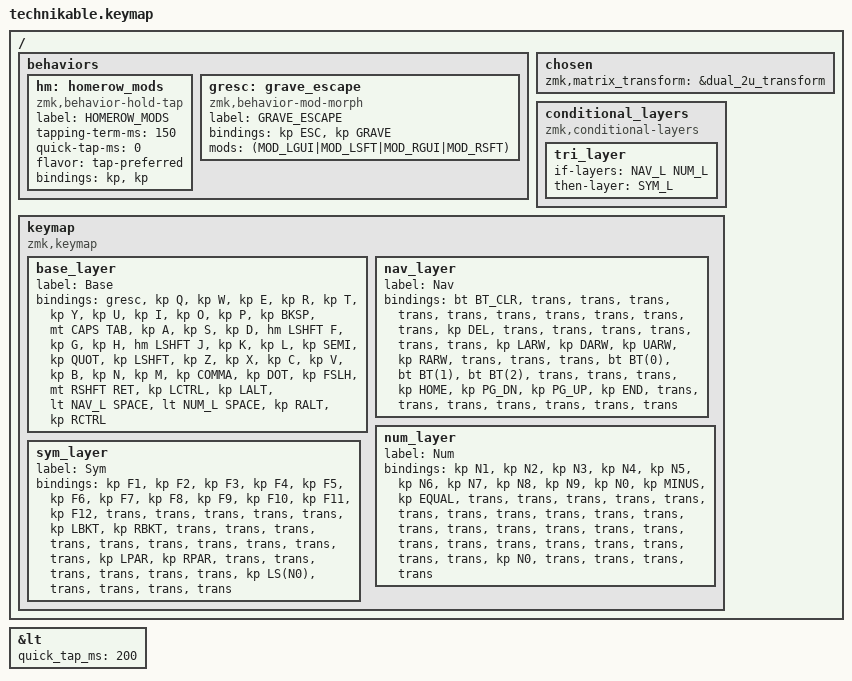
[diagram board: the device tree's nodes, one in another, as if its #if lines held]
/*
 * Copyright (c) 2022 Pete Johanson
 *
 * SPDX-License-Identifier: MIT
 */

#include <behaviors.dtsi>
#include <dt-bindings/zmk/keys.h>
#include <dt-bindings/zmk/bt.h>
#include <dt-bindings/zmk/outputs.h>

#define QWERTY_BASE 1

// #define TBLE_ORTHO   true
#define TBLE_MIT     true
// #define TBLE_DUAL_2U true

#define BAS_L 0
#define NAV_L 1
#define NUM_L 2
#define SYM_L 3

// Using layer taps on thumbs, having quick tap as well helps w/ repeating space/backspace
&lt { quick_tap_ms = <200>; };

#define BT(n) BT_SEL n

/ {
    behaviors {
        hm: homerow_mods {
	    compatible = "zmk,behavior-hold-tap";
	    label = "HOMEROW_MODS";
	    #binding-cells = <2>;
	    tapping-term-ms = <150>;
	    quick-tap-ms = <0>;
	    flavor = "tap-preferred";
	    bindings = <&kp>, <&kp>;
        };
        gresc: grave_escape {
            compatible = "zmk,behavior-mod-morph";
            label = "GRAVE_ESCAPE";
            #binding-cells = <0>;
            bindings = <&kp ESC>, <&kp GRAVE>;
            mods = <(MOD_LGUI|MOD_LSFT|MOD_RGUI|MOD_RSFT)>;
        };
    };
    chosen {
       zmk,matrix_transform =
#ifdef TBLE_DUAL_2U
                       &dual_2u_transform;
#elif defined(TBLE_MIT)
                       &mit_transform;
#else
                       &ortho_transform;
#endif
    };

    conditional_layers {
        compatible = "zmk,conditional-layers";
	tri_layer {
	    if-layers = <NAV_L NUM_L>;
	    then-layer = <SYM_L>;
	};
    };

    keymap {
        compatible = "zmk,keymap";

        base_layer {
            label = "Base";
            bindings = <
#ifdef QWERTY_BASE
 &gresc    &kp Q      &kp W      &kp E     &kp R           &kp T          &kp Y         &kp U            &kp I       &kp O      &kp P         &kp BKSP
 &mt CAPS TAB    &kp A      &kp S      &kp D     &hm LSHFT F     &kp G          &kp H         &hm LSHFT J      &kp K       &kp L      &kp SEMI      &kp QUOT
 &kp LSHFT       &kp Z      &kp X      &kp C     &kp V           &kp B          &kp N         &kp M            &kp COMMA   &kp DOT    &kp FSLH      &mt RSHFT RET
#else
 &kp ESC    &kp Q      &kp W      &kp F       &kp P          &kp B          &kp J            &kp L          &kp U       &kp Y      &kp QUOT     &kp BKSP
 &kp TAB    &kp A      &kp R      &kp S       &kp T          &kp G          &kp M            &kp N          &kp E       &kp I      &kp O        &kp QUOT
 &kp LSHFT  &kp Z      &kp X      &kp C       &kp D          &kp V          &kp K            &kp H          &kp COMMA   &kp DOT    &kp FSLH     &kp RET
#endif
#ifdef TBLE_DUAL_2U
                       &kp LCTRL  &kp LALT      &lt NAV_L SPACE                &lt NUM_L SPACE              &kp RALT    &kp RCTRL
#elif defined(TBLE_MIT)
                       &kp LCTRL  &kp LGUI    &lt NAV_L LBKT     &kp SPACE       &lt NUM_L RBKT      &kp LALT    &kp GRAVE
#else
                       &kp LCTRL  &kp LALT    &mo NAV_L      &kp SPACE      &kp SPACE        &mo NUM_L      &kp RALT    &kp RCTRL
#endif
            >;
        };

        nav_layer {
            label = "Nav";
            bindings = <
&bt BT_CLR &trans     &trans     &trans      &trans          &trans       &trans         &trans      &trans     &trans     &trans     &kp DEL
&trans     &trans     &trans     &trans      &trans          &trans       &kp LARW       &kp DARW    &kp UARW   &kp RARW   &trans     &trans
&trans     &bt BT(0)  &bt BT(1)  &bt BT(2)   &trans          &trans       &trans         &kp HOME    &kp PG_DN  &kp PG_UP  &kp END    &trans
#ifdef TBLE_DUAL_2U
                      &trans     &trans              &trans                    &trans       &trans         &trans
#elif defined(TBLE_MIT)
                      &trans     &trans      &trans                &trans             &trans      &trans   &trans
#else
                      &trans     &trans      &trans          &trans       &trans    &trans  &trans         &trans
#endif
            >;
        };

        num_layer {
            label = "Num";
            bindings = <
&kp N1     &kp N2     &kp N3     &kp N4      &kp N5    &kp N6      &kp N7        &kp N8         &kp N9          &kp N0       &kp MINUS  &kp EQUAL
&trans     &trans     &trans     &trans      &trans    &trans      &trans        &trans         &trans       &trans       &trans     &trans
&trans     &trans     &trans     &trans      &trans    &trans      &trans        &trans         &trans       &trans       &trans     &trans
#ifdef TBLE_DUAL_2U
                     &trans     &kp N0              &trans                 &trans            &trans         &trans
#elif defined(TBLE_MIT)
                     &trans     &kp N0      &trans           &none            &kp ESC        &kp DEL      &trans
#else
                     &trans     &kp N0      &trans    &none         &none     &kp ESC        &kp DEL      &trans
#endif
            >;
        };

        sym_layer {
            label = "Sym";
            bindings = <
&kp F1     &kp F2     &kp F3     &kp F4      &kp F5       &kp F6       &kp F7       &kp F8    &kp F9       &kp F10      &kp F11    &kp F12
&trans     &trans     &trans     &trans      &trans       &kp LBKT     &kp RBKT     &trans    &trans       &trans       &trans     &trans
&trans     &trans     &trans     &trans      &trans       &kp LPAR     &kp RPAR     &trans    &trans       &trans       &trans     &trans
#ifdef TBLE_DUAL_2U
                      &trans     &kp LS(N0)              &trans                    &trans       &trans         &trans
#elif defined(TBLE_MIT)
                      &trans     &trans          &trans                &trans             &trans      &trans   &trans
#else
                      &trans     &kp LS(N0)      &trans          &trans       &trans    &trans  &trans         &trans
#endif
            >;
        };

    };
};

